AUTOSAR XML (schema 00046)
package /ComponentTypes
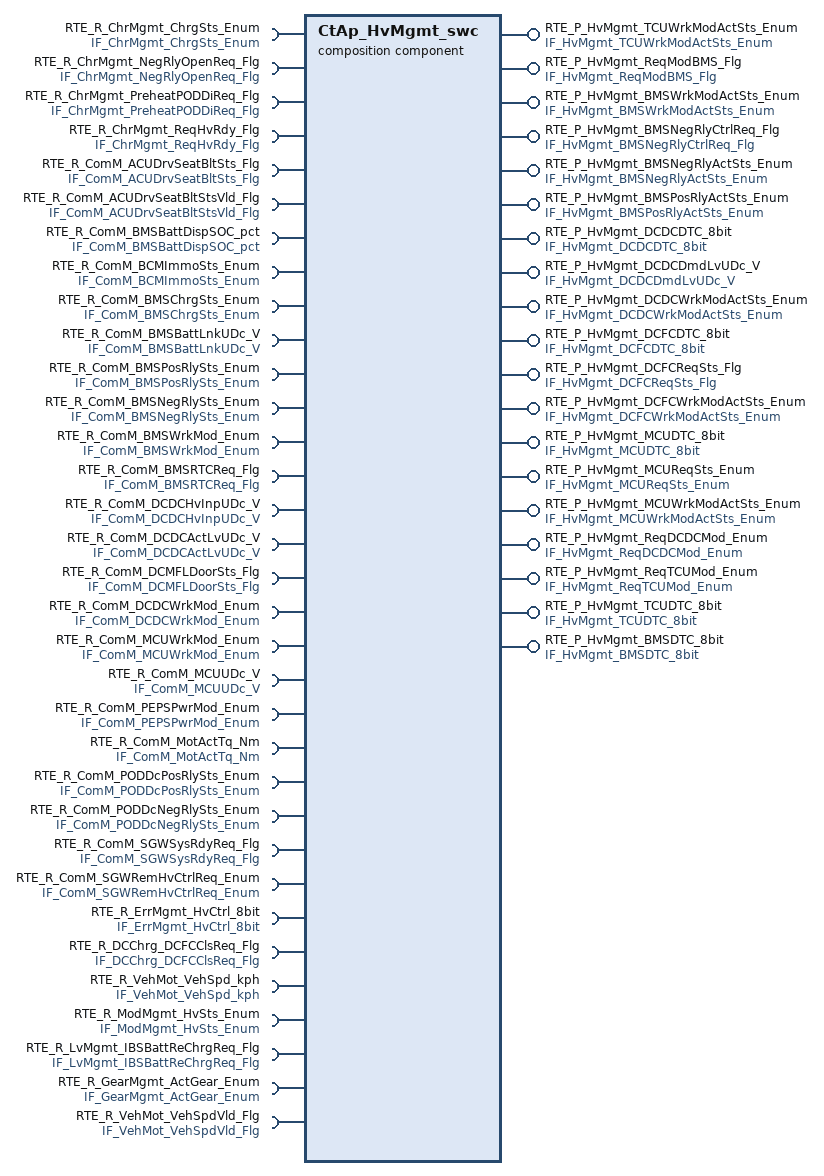
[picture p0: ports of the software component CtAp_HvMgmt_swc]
  composition sw component type CtAp_HvMgmt_swc
    6 x provide port:
      RTE_P_HvMgmt_TCUWrkModActSts_Enum: nonqueued-sender-com-spec=tec_HvMgmt_TCUWrkModActSts_Enum, provided-interface=IF_HvMgmt_TCUWrkModActSts_Enum
      RTE_P_HvMgmt_ReqModBMS_Flg: nonqueued-sender-com-spec=tec_HvMgmt_ReqModBMS_Flg, provided-interface=IF_HvMgmt_ReqModBMS_Flg
      RTE_P_HvMgmt_BMSWrkModActSts_Enum: nonqueued-sender-com-spec=tec_HvMgmt_BMSWrkModActSts_Enum, provided-interface=IF_HvMgmt_BMSWrkModActSts_Enum
      RTE_P_HvMgmt_BMSNegRlyCtrlReq_Flg: nonqueued-sender-com-spec=tec_HvMgmt_BMSNegRlyCtrlReq_Flg, provided-interface=IF_HvMgmt_BMSNegRlyCtrlReq_Flg
      RTE_P_HvMgmt_BMSNegRlyActSts_Enum: nonqueued-sender-com-spec=tec_HvMgmt_BMSNegRlyActSts_Enum, provided-interface=IF_HvMgmt_BMSNegRlyActSts_Enum
      RTE_P_HvMgmt_BMSPosRlyActSts_Enum: nonqueued-sender-com-spec=tec_HvMgmt_BMSPosRlyActSts_Enum, provided-interface=IF_HvMgmt_BMSPosRlyActSts_Enum
    33 x require port:
      RTE_R_ChrMgmt_ChrgSts_Enum: nonqueued-receiver-com-spec{data-element=tec_ChrMgmt_ChrgSts_Enum, filter=data-filter-type=ALWAYS}, required-interface=IF_ChrMgmt_ChrgSts_Enum
      RTE_R_ChrMgmt_NegRlyOpenReq_Flg: nonqueued-receiver-com-spec{data-element=tec_ChrMgmt_NegRlyOpenReq_Flg, filter=data-filter-type=ALWAYS}, required-interface=IF_ChrMgmt_NegRlyOpenReq_Flg
      RTE_R_ChrMgmt_PreheatPODDiReq_Flg: nonqueued-receiver-com-spec{data-element=tec_ChrMgmt_PreheatPODDiReq_Flg, filter=data-filter-type=ALWAYS}, required-interface=IF_ChrMgmt_PreheatPODDiReq_Flg
      RTE_R_ChrMgmt_ReqHvRdy_Flg: nonqueued-receiver-com-spec{data-element=tec_ChrMgmt_ReqHvRdy_Flg, filter=data-filter-type=ALWAYS}, required-interface=IF_ChrMgmt_ReqHvRdy_Flg
      RTE_R_ComM_ACUDrvSeatBltSts_Flg: nonqueued-receiver-com-spec{data-element=tec_ComM_ACUDrvSeatBltSts_Flg, filter=data-filter-type=ALWAYS}, required-interface=IF_ComM_ACUDrvSeatBltSts_Flg
      RTE_R_ComM_ACUDrvSeatBltStsVld_Flg: nonqueued-receiver-com-spec{data-element=tec_ComM_ACUDrvSeatBltStsVld_Flg, filter=data-filter-type=ALWAYS}, required-interface=IF_ComM_ACUDrvSeatBltStsVld_Flg
      RTE_R_ComM_BMSBattDispSOC_pct: nonqueued-receiver-com-spec{data-element=tec_ComM_BMSBattDispSOC_pct, filter=data-filter-type=ALWAYS}, required-interface=IF_ComM_BMSBattDispSOC_pct
      RTE_R_ComM_BCMImmoSts_Enum: nonqueued-receiver-com-spec{data-element=tec_ComM_BCMImmoSts_Enum, filter=data-filter-type=ALWAYS}, required-interface=IF_ComM_BCMImmoSts_Enum
      RTE_R_ComM_BMSChrgSts_Enum: nonqueued-receiver-com-spec{data-element=tec_ComM_BMSChrgSts_Enum, filter=data-filter-type=ALWAYS}, required-interface=IF_ComM_BMSChrgSts_Enum
      RTE_R_ComM_BMSBattLnkUDc_V: nonqueued-receiver-com-spec{data-element=tec_ComM_BMSBattLnkUDc_V, filter=data-filter-type=ALWAYS}, required-interface=IF_ComM_BMSBattLnkUDc_V
      RTE_R_ComM_BMSPosRlySts_Enum: nonqueued-receiver-com-spec{data-element=tec_ComM_BMSPosRlySts_Enum, filter=data-filter-type=ALWAYS}, required-interface=IF_ComM_BMSPosRlySts_Enum
      RTE_R_ComM_BMSNegRlySts_Enum: nonqueued-receiver-com-spec{data-element=tec_ComM_BMSNegRlySts_Enum, filter=data-filter-type=ALWAYS}, required-interface=IF_ComM_BMSNegRlySts_Enum
      RTE_R_ComM_BMSWrkMod_Enum: nonqueued-receiver-com-spec{data-element=tec_ComM_BMSWrkMod_Enum, filter=data-filter-type=ALWAYS}, required-interface=IF_ComM_BMSWrkMod_Enum
      RTE_R_ComM_BMSRTCReq_Flg: nonqueued-receiver-com-spec{data-element=tec_ComM_BMSRTCReq_Flg, filter=data-filter-type=ALWAYS}, required-interface=IF_ComM_BMSRTCReq_Flg
      RTE_R_ComM_DCDCHvInpUDc_V: nonqueued-receiver-com-spec{data-element=tec_ComM_DCDCHvInpUDc_V, filter=data-filter-type=ALWAYS}, required-interface=IF_ComM_DCDCHvInpUDc_V
      RTE_R_ComM_DCDCActLvUDc_V: nonqueued-receiver-com-spec{data-element=tec_ComM_DCDCActLvUDc_V, filter=data-filter-type=ALWAYS}, required-interface=IF_ComM_DCDCActLvUDc_V
      RTE_R_ComM_DCMFLDoorSts_Flg: nonqueued-receiver-com-spec{data-element=tec_ComM_DCMFLDoorSts_Flg, filter=data-filter-type=ALWAYS}, required-interface=IF_ComM_DCMFLDoorSts_Flg
      RTE_R_ComM_DCDCWrkMod_Enum: nonqueued-receiver-com-spec{data-element=tec_ComM_DCDCWrkMod_Enum, filter=data-filter-type=ALWAYS}, required-interface=IF_ComM_DCDCWrkMod_Enum
      RTE_R_ComM_MCUWrkMod_Enum: nonqueued-receiver-com-spec{data-element=tec_ComM_MCUWrkMod_Enum, filter=data-filter-type=ALWAYS}, required-interface=IF_ComM_MCUWrkMod_Enum
      RTE_R_ComM_MCUUDc_V: nonqueued-receiver-com-spec{data-element=tec_ComM_MCUUDc_V, filter=data-filter-type=ALWAYS}, required-interface=IF_ComM_MCUUDc_V
      RTE_R_ComM_PEPSPwrMod_Enum: nonqueued-receiver-com-spec{data-element=tec_ComM_PEPSPwrMod_Enum, filter=data-filter-type=ALWAYS}, required-interface=IF_ComM_PEPSPwrMod_Enum
      RTE_R_ComM_MotActTq_Nm: nonqueued-receiver-com-spec{data-element=tec_ComM_MotActTq_Nm, filter=data-filter-type=ALWAYS}, required-interface=IF_ComM_MotActTq_Nm
      RTE_R_ComM_PODDcPosRlySts_Enum: nonqueued-receiver-com-spec{data-element=tec_ComM_PODDcPosRlySts_Enum, filter=data-filter-type=ALWAYS}, required-interface=IF_ComM_PODDcPosRlySts_Enum
      RTE_R_ComM_PODDcNegRlySts_Enum: nonqueued-receiver-com-spec{data-element=tec_ComM_PODDcNegRlySts_Enum, filter=data-filter-type=ALWAYS}, required-interface=IF_ComM_PODDcNegRlySts_Enum
      RTE_R_ComM_SGWSysRdyReq_Flg: nonqueued-receiver-com-spec{data-element=tec_ComM_SGWSysRdyReq_Flg, filter=data-filter-type=ALWAYS}, required-interface=IF_ComM_SGWSysRdyReq_Flg
      RTE_R_ComM_SGWRemHvCtrlReq_Enum: nonqueued-receiver-com-spec{data-element=tec_ComM_SGWRemHvCtrlReq_Enum, filter=data-filter-type=ALWAYS}, required-interface=IF_ComM_SGWRemHvCtrlReq_Enum
      RTE_R_ErrMgmt_HvCtrl_8bit: nonqueued-receiver-com-spec{data-element=tec_ErrMgmt_HvCtrl_8bit, filter=data-filter-type=ALWAYS}, required-interface=IF_ErrMgmt_HvCtrl_8bit
      RTE_R_DCChrg_DCFCClsReq_Flg: nonqueued-receiver-com-spec{data-element=tec_DCChrg_DCFCClsReq_Flg, filter=data-filter-type=ALWAYS}, required-interface=IF_DCChrg_DCFCClsReq_Flg
      RTE_R_VehMot_VehSpd_kph: nonqueued-receiver-com-spec{data-element=tec_VehMot_VehSpd_kph, filter=data-filter-type=ALWAYS}, required-interface=IF_VehMot_VehSpd_kph
      RTE_R_ModMgmt_HvSts_Enum: nonqueued-receiver-com-spec{data-element=tec_ModMgmt_HvSts_Enum, filter=data-filter-type=ALWAYS}, required-interface=IF_ModMgmt_HvSts_Enum
      RTE_R_LvMgmt_IBSBattReChrgReq_Flg: nonqueued-receiver-com-spec{data-element=tec_LvMgmt_IBSBattReChrgReq_Flg, filter=data-filter-type=ALWAYS}, required-interface=IF_LvMgmt_IBSBattReChrgReq_Flg
      RTE_R_GearMgmt_ActGear_Enum: nonqueued-receiver-com-spec{data-element=tec_GearMgmt_ActGear_Enum, filter=data-filter-type=ALWAYS}, required-interface=IF_GearMgmt_ActGear_Enum
      RTE_R_VehMot_VehSpdVld_Flg: nonqueued-receiver-com-spec{data-element=tec_VehMot_VehSpdVld_Flg, filter=data-filter-type=ALWAYS}, required-interface=IF_VehMot_VehSpdVld_Flg
    13 x provide port:
      RTE_P_HvMgmt_DCDCDTC_8bit: nonqueued-sender-com-spec=tec_HvMgmt_DCDCDTC_8bit, provided-interface=IF_HvMgmt_DCDCDTC_8bit
      RTE_P_HvMgmt_DCDCDmdLvUDc_V: nonqueued-sender-com-spec=tec_HvMgmt_DCDCDmdLvUDc_V, provided-interface=IF_HvMgmt_DCDCDmdLvUDc_V
      RTE_P_HvMgmt_DCDCWrkModActSts_Enum: nonqueued-sender-com-spec=tec_HvMgmt_DCDCWrkModActSts_Enum, provided-interface=IF_HvMgmt_DCDCWrkModActSts_Enum
      RTE_P_HvMgmt_DCFCDTC_8bit: nonqueued-sender-com-spec=tec_HvMgmt_DCFCDTC_8bit, provided-interface=IF_HvMgmt_DCFCDTC_8bit
      RTE_P_HvMgmt_DCFCReqSts_Flg: nonqueued-sender-com-spec=tec_HvMgmt_DCFCReqSts_Flg, provided-interface=IF_HvMgmt_DCFCReqSts_Flg
      RTE_P_HvMgmt_DCFCWrkModActSts_Enum: nonqueued-sender-com-spec=tec_HvMgmt_DCFCWrkModActSts_Enum, provided-interface=IF_HvMgmt_DCFCWrkModActSts_Enum
      RTE_P_HvMgmt_MCUDTC_8bit: nonqueued-sender-com-spec=tec_HvMgmt_MCUDTC_8bit, provided-interface=IF_HvMgmt_MCUDTC_8bit
      RTE_P_HvMgmt_MCUReqSts_Enum: nonqueued-sender-com-spec=tec_HvMgmt_MCUReqSts_Enum, provided-interface=IF_HvMgmt_MCUReqSts_Enum
      RTE_P_HvMgmt_MCUWrkModActSts_Enum: nonqueued-sender-com-spec=tec_HvMgmt_MCUWrkModActSts_Enum, provided-interface=IF_HvMgmt_MCUWrkModActSts_Enum
      RTE_P_HvMgmt_ReqDCDCMod_Enum: nonqueued-sender-com-spec=tec_HvMgmt_ReqDCDCMod_Enum, provided-interface=IF_HvMgmt_ReqDCDCMod_Enum
      RTE_P_HvMgmt_ReqTCUMod_Enum: nonqueued-sender-com-spec=tec_HvMgmt_ReqTCUMod_Enum, provided-interface=IF_HvMgmt_ReqTCUMod_Enum
      RTE_P_HvMgmt_TCUDTC_8bit: nonqueued-sender-com-spec=tec_HvMgmt_TCUDTC_8bit, provided-interface=IF_HvMgmt_TCUDTC_8bit
      RTE_P_HvMgmt_BMSDTC_8bit: nonqueued-sender-com-spec=tec_HvMgmt_BMSDTC_8bit, provided-interface=IF_HvMgmt_BMSDTC_8bit
    5 x component:
      CtAp_BMSMgmt: type=CtAp_BMSMgmt
      CtAp_DCFCMgmt: type=CtAp_DCFCMgmt
      CtAp_MCUMgmt: type=CtAp_MCUMgmt
      CtAp_DCDCMgmt: type=CtAp_DCDCMgmt
      CtAp_TCUMgmt: type=CtAp_TCUMgmt
    delegate CtAp_BMSMgmt.RTE_R_ChrMgmt_ChrgSts_Enum <-> outer port RTE_R_ChrMgmt_ChrgSts_Enum
    delegate CtAp_BMSMgmt.RTE_R_ChrMgmt_NegRlyOpenReq_Flg <-> outer port RTE_R_ChrMgmt_NegRlyOpenReq_Flg
    delegate CtAp_BMSMgmt.RTE_R_ChrMgmt_ReqHvRdy_Flg <-> outer port RTE_R_ChrMgmt_ReqHvRdy_Flg
    delegate CtAp_BMSMgmt.RTE_R_ComM_BMSBattDispSOC_pct <-> outer port RTE_R_ComM_BMSBattDispSOC_pct
    delegate CtAp_BMSMgmt.RTE_R_ComM_BMSBattLnkUDc_V <-> outer port RTE_R_ComM_BMSBattLnkUDc_V
    delegate CtAp_BMSMgmt.RTE_R_ComM_BMSNegRlySts_Enum <-> outer port RTE_R_ComM_BMSNegRlySts_Enum
    delegate CtAp_BMSMgmt.RTE_R_ComM_BMSPosRlySts_Enum <-> outer port RTE_R_ComM_BMSPosRlySts_Enum
    delegate CtAp_BMSMgmt.RTE_R_ComM_BMSRTCReq_Flg <-> outer port RTE_R_ComM_BMSRTCReq_Flg
    delegate CtAp_BMSMgmt.RTE_R_ComM_BMSWrkMod_Enum <-> outer port RTE_R_ComM_BMSWrkMod_Enum
    delegate CtAp_BMSMgmt.RTE_R_ComM_DCDCHvInpUDc_V <-> outer port RTE_R_ComM_DCDCHvInpUDc_V
    delegate CtAp_BMSMgmt.RTE_R_ComM_MCUUDc_V <-> outer port RTE_R_ComM_MCUUDc_V
    delegate CtAp_BMSMgmt.RTE_R_ComM_PEPSPwrMod_Enum <-> outer port RTE_R_ComM_PEPSPwrMod_Enum
    delegate CtAp_BMSMgmt.RTE_R_ComM_SGWRemHvCtrlReq_Enum <-> outer port RTE_R_ComM_SGWRemHvCtrlReq_Enum
    delegate CtAp_BMSMgmt.RTE_R_ErrMgmt_HvCtrl_8bit <-> outer port RTE_R_ErrMgmt_HvCtrl_8bit
    delegate CtAp_BMSMgmt.RTE_R_GearMgmt_ActGear_Enum <-> outer port RTE_R_GearMgmt_ActGear_Enum
    delegate CtAp_BMSMgmt.RTE_R_LvMgmt_IBSBattReChrgReq_Flg <-> outer port RTE_R_LvMgmt_IBSBattReChrgReq_Flg
    delegate CtAp_BMSMgmt.RTE_R_ModMgmt_HvSts_Enum <-> outer port RTE_R_ModMgmt_HvSts_Enum
    delegate CtAp_BMSMgmt.RTE_R_VehMot_VehSpd_kph <-> outer port RTE_R_VehMot_VehSpd_kph
    delegate CtAp_BMSMgmt.RTE_R_VehMot_VehSpdVld_Flg <-> outer port RTE_R_VehMot_VehSpdVld_Flg
    delegate CtAp_DCDCMgmt.RTE_R_ChrMgmt_ChrgSts_Enum <-> outer port RTE_R_ChrMgmt_ChrgSts_Enum
    delegate CtAp_DCDCMgmt.RTE_R_ChrMgmt_PreheatPODDiReq_Flg <-> outer port RTE_R_ChrMgmt_PreheatPODDiReq_Flg
    delegate CtAp_DCDCMgmt.RTE_R_ComM_BMSBattLnkUDc_V <-> outer port RTE_R_ComM_BMSBattLnkUDc_V
    delegate CtAp_DCDCMgmt.RTE_R_ComM_BMSChrgSts_Enum <-> outer port RTE_R_ComM_BMSChrgSts_Enum
    delegate CtAp_DCDCMgmt.RTE_R_ComM_DCDCActLvUDc_V <-> outer port RTE_R_ComM_DCDCActLvUDc_V
    delegate CtAp_DCDCMgmt.RTE_R_ComM_DCDCHvInpUDc_V <-> outer port RTE_R_ComM_DCDCHvInpUDc_V
    delegate CtAp_DCDCMgmt.RTE_R_ComM_DCDCWrkMod_Enum <-> outer port RTE_R_ComM_DCDCWrkMod_Enum
    delegate CtAp_DCDCMgmt.RTE_R_ErrMgmt_HvCtrl_8bit <-> outer port RTE_R_ErrMgmt_HvCtrl_8bit
    connect CtAp_BMSMgmt.RTE_P_HvMgmt_BMSNormHvDwnReq_Flg -> CtAp_DCDCMgmt.RTE_R_HvMgmt_BMSNormHvDwnReq_Flg
    delegate CtAp_DCDCMgmt.RTE_R_ModMgmt_HvSts_Enum <-> outer port RTE_R_ModMgmt_HvSts_Enum
    delegate CtAp_DCFCMgmt.RTE_R_ComM_PODDcNegRlySts_Enum <-> outer port RTE_R_ComM_PODDcNegRlySts_Enum
    delegate CtAp_DCFCMgmt.RTE_R_ComM_PODDcPosRlySts_Enum <-> outer port RTE_R_ComM_PODDcPosRlySts_Enum
    delegate CtAp_DCFCMgmt.RTE_R_DCChrg_DCFCClsReq_Flg <-> outer port RTE_R_DCChrg_DCFCClsReq_Flg
    delegate CtAp_MCUMgmt.RTE_R_ChrMgmt_ChrgSts_Enum <-> outer port RTE_R_ChrMgmt_ChrgSts_Enum
    delegate CtAp_MCUMgmt.RTE_R_ComM_ACUDrvSeatBltSts_Flg <-> outer port RTE_R_ComM_ACUDrvSeatBltSts_Flg
    delegate CtAp_MCUMgmt.RTE_R_ComM_ACUDrvSeatBltStsVld_Flg <-> outer port RTE_R_ComM_ACUDrvSeatBltStsVld_Flg
    delegate CtAp_MCUMgmt.RTE_R_ComM_BCMImmoSts_Enum <-> outer port RTE_R_ComM_BCMImmoSts_Enum
    delegate CtAp_MCUMgmt.RTE_R_ComM_DCMFLDoorSts_Flg <-> outer port RTE_R_ComM_DCMFLDoorSts_Flg
    delegate CtAp_MCUMgmt.RTE_R_ComM_MCUWrkMod_Enum <-> outer port RTE_R_ComM_MCUWrkMod_Enum
    delegate CtAp_MCUMgmt.RTE_R_ComM_PEPSPwrMod_Enum <-> outer port RTE_R_ComM_PEPSPwrMod_Enum
    delegate CtAp_MCUMgmt.RTE_R_ComM_SGWSysRdyReq_Flg <-> outer port RTE_R_ComM_SGWSysRdyReq_Flg
    delegate CtAp_MCUMgmt.RTE_R_ErrMgmt_HvCtrl_8bit <-> outer port RTE_R_ErrMgmt_HvCtrl_8bit
    delegate CtAp_MCUMgmt.RTE_R_GearMgmt_ActGear_Enum <-> outer port RTE_R_GearMgmt_ActGear_Enum
    connect CtAp_BMSMgmt.RTE_P_HvMgmt_BMSWrkModActSts_Enum -> CtAp_MCUMgmt.RTE_R_HvMgmt_BMSWrkModActSts_Enum
    delegate CtAp_MCUMgmt.RTE_R_ModMgmt_HvSts_Enum <-> outer port RTE_R_ModMgmt_HvSts_Enum
    delegate CtAp_TCUMgmt.RTE_R_ComM_MotActTq_Nm <-> outer port RTE_R_ComM_MotActTq_Nm
    delegate CtAp_TCUMgmt.RTE_R_ErrMgmt_HvCtrl_8bit <-> outer port RTE_R_ErrMgmt_HvCtrl_8bit
    connect CtAp_BMSMgmt.RTE_P_HvMgmt_BMSNormHvDwnReq_Flg -> CtAp_TCUMgmt.RTE_R_HvMgmt_BMSNormHvDwnReq_Flg
    connect CtAp_DCDCMgmt.RTE_P_HvMgmt_DCDCWrkModActSts_Enum -> CtAp_TCUMgmt.RTE_R_HvMgmt_DCDCWrkModActSts_Enum
    delegate CtAp_TCUMgmt.RTE_R_ModMgmt_HvSts_Enum <-> outer port RTE_R_ModMgmt_HvSts_Enum
    connect CtAp_TCUMgmt.RTE_P_HvMgmt_TCUWrkModActSts_Enum -> CtAp_BMSMgmt.RTE_R_HvMgmt_TCUWrkModActSts_Enum
    delegate CtAp_BMSMgmt.RTE_P_HvMgmt_BMSNegRlyActSts_Enum <-> outer port RTE_P_HvMgmt_BMSNegRlyActSts_Enum
    delegate CtAp_BMSMgmt.RTE_P_HvMgmt_BMSNegRlyCtrlReq_Flg <-> outer port RTE_P_HvMgmt_BMSNegRlyCtrlReq_Flg
    delegate CtAp_BMSMgmt.RTE_P_HvMgmt_BMSPosRlyActSts_Enum <-> outer port RTE_P_HvMgmt_BMSPosRlyActSts_Enum
    delegate CtAp_BMSMgmt.RTE_P_HvMgmt_ReqModBMS_Flg <-> outer port RTE_P_HvMgmt_ReqModBMS_Flg
    delegate CtAp_DCDCMgmt.RTE_P_HvMgmt_DCDCDmdLvUDc_V <-> outer port RTE_P_HvMgmt_DCDCDmdLvUDc_V
    delegate CtAp_DCDCMgmt.RTE_P_HvMgmt_DCDCDTC_8bit <-> outer port RTE_P_HvMgmt_DCDCDTC_8bit
    delegate CtAp_DCDCMgmt.RTE_P_HvMgmt_ReqDCDCMod_Enum <-> outer port RTE_P_HvMgmt_ReqDCDCMod_Enum
    delegate CtAp_DCFCMgmt.RTE_P_HvMgmt_DCFCDTC_8bit <-> outer port RTE_P_HvMgmt_DCFCDTC_8bit
    delegate CtAp_DCFCMgmt.RTE_P_HvMgmt_DCFCReqSts_Flg <-> outer port RTE_P_HvMgmt_DCFCReqSts_Flg
    delegate CtAp_DCFCMgmt.RTE_P_HvMgmt_DCFCWrkModActSts_Enum <-> outer port RTE_P_HvMgmt_DCFCWrkModActSts_Enum
    delegate CtAp_MCUMgmt.RTE_P_HvMgmt_MCUDTC_8bit <-> outer port RTE_P_HvMgmt_MCUDTC_8bit
    delegate CtAp_MCUMgmt.RTE_P_HvMgmt_MCUReqSts_Enum <-> outer port RTE_P_HvMgmt_MCUReqSts_Enum
    delegate CtAp_MCUMgmt.RTE_P_HvMgmt_MCUWrkModActSts_Enum <-> outer port RTE_P_HvMgmt_MCUWrkModActSts_Enum
    delegate CtAp_TCUMgmt.RTE_P_HvMgmt_ReqTCUMod_Enum <-> outer port RTE_P_HvMgmt_ReqTCUMod_Enum
    delegate CtAp_TCUMgmt.RTE_P_HvMgmt_TCUDTC_8bit <-> outer port RTE_P_HvMgmt_TCUDTC_8bit
    delegate CtAp_BMSMgmt.RTE_P_HvMgmt_BMSDTC_8bit <-> outer port RTE_P_HvMgmt_BMSDTC_8bit
    delegate CtAp_TCUMgmt.RTE_P_HvMgmt_TCUWrkModActSts_Enum <-> outer port RTE_P_HvMgmt_TCUWrkModActSts_Enum
    delegate CtAp_DCDCMgmt.RTE_P_HvMgmt_DCDCWrkModActSts_Enum <-> outer port RTE_P_HvMgmt_DCDCWrkModActSts_Enum
    delegate CtAp_BMSMgmt.RTE_P_HvMgmt_BMSWrkModActSts_Enum <-> outer port RTE_P_HvMgmt_BMSWrkModActSts_Enum
